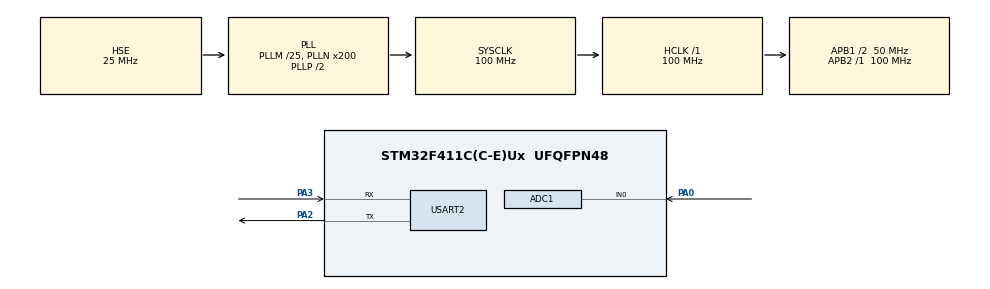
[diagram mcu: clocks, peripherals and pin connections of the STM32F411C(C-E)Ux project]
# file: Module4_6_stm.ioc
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ADC1.Channel-0\#ChannelRegularConversion=ADC_CHANNEL_0
ADC1.ContinuousConvMode=ENABLE
ADC1.DMAContinuousRequests=ENABLE
ADC1.NbrOfConversionFlag=1
ADC1.Rank-0\#ChannelRegularConversion=1
ADC1.SamplingTime-0\#ChannelRegularConversion=ADC_SAMPLETIME_84CYCLES
ADC1.master=1
Dma.ADC1.0.Direction=DMA_PERIPH_TO_MEMORY
Dma.ADC1.0.FIFOMode=DMA_FIFOMODE_DISABLE
Dma.ADC1.0.Instance=DMA2_Stream0
Dma.ADC1.0.MemDataAlignment=DMA_MDATAALIGN_HALFWORD
Dma.ADC1.0.MemInc=DMA_MINC_ENABLE
Dma.ADC1.0.Mode=DMA_CIRCULAR
Dma.ADC1.0.PeriphDataAlignment=DMA_PDATAALIGN_HALFWORD
Dma.ADC1.0.PeriphInc=DMA_PINC_DISABLE
Dma.ADC1.0.Priority=DMA_PRIORITY_LOW
Dma.Request0=ADC1
Dma.Request1=USART2_TX
Dma.USART2_TX.1.Direction=DMA_MEMORY_TO_PERIPH
Dma.USART2_TX.1.FIFOMode=DMA_FIFOMODE_DISABLE
Dma.USART2_TX.1.Instance=DMA1_Stream6
Dma.USART2_TX.1.MemDataAlignment=DMA_MDATAALIGN_BYTE
Dma.USART2_TX.1.MemInc=DMA_MINC_ENABLE
Dma.USART2_TX.1.Mode=DMA_NORMAL
Dma.USART2_TX.1.PeriphDataAlignment=DMA_PDATAALIGN_BYTE
Dma.USART2_TX.1.PeriphInc=DMA_PINC_DISABLE
Dma.USART2_TX.1.Priority=DMA_PRIORITY_LOW
Mcu.Family=STM32F4
Mcu.Name=STM32F411C(C-E)Ux
Mcu.Package=UFQFPN48
NVIC.DMA1_Stream6_IRQn=true\:0\:0\:false\:false\:true\:false\:true\:true
NVIC.DMA2_Stream0_IRQn=true\:0\:0\:false\:false\:true\:false\:true\:true
NVIC.PriorityGroup=NVIC_PRIORITYGROUP_4
NVIC.USART2_IRQn=true\:0\:0\:false\:false\:true\:false\:true\:true
PA0-WKUP.Signal=ADCx_IN0
PA13.Mode=Serial_Wire
PA13.Signal=SYS_JTMS-SWDIO
PA14.Mode=Serial_Wire
PA14.Signal=SYS_JTCK-SWCLK
PA2.Mode=Asynchronous
PA2.Signal=USART2_TX
PA3.Mode=Asynchronous
PA3.Signal=USART2_RX
PH0\ -\ OSC_IN.Mode=HSE-External-Oscillator
PH0\ -\ OSC_IN.Signal=RCC_OSC_IN
PH1\ -\ OSC_OUT.Mode=HSE-External-Oscillator
PH1\ -\ OSC_OUT.Signal=RCC_OSC_OUT
ProjectManager.HeapSize=0x200
ProjectManager.StackSize=0x400
ProjectManager.TargetToolchain=STM32CubeIDE
RCC.48MHZClocksFreq_Value=50000000
RCC.AHBFreq_Value=100000000
RCC.APB1CLKDivider=RCC_HCLK_DIV2
RCC.APB1Freq_Value=50000000
RCC.APB1TimFreq_Value=100000000
RCC.APB2Freq_Value=100000000
RCC.APB2TimFreq_Value=100000000
RCC.CortexFreq_Value=100000000
RCC.HCLKFreq_Value=100000000
RCC.HSE_VALUE=25000000
RCC.HSI_VALUE=16000000
RCC.LSE_VALUE=32768
RCC.PLLM=25
RCC.PLLN=200
RCC.PLLSourceVirtual=RCC_PLLSOURCE_HSE
RCC.SYSCLKFreq_VALUE=100000000
RCC.SYSCLKSource=RCC_SYSCLKSOURCE_PLLCLK
RCC.VCOOutputFreq_Value=200000000
SH.ADCx_IN0.0=ADC1_IN0,IN0
USART2.VirtualMode=VM_ASYNC
board=custom

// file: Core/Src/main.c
/* USER CODE BEGIN Header */
/**
  ******************************************************************************
  * @file           : main.c
  * @brief          : Main program body
  ******************************************************************************
  * @attention
  *
  * Copyright (c) 2026 STMicroelectronics.
  * All rights reserved.
  *
  * This software is licensed under terms that can be found in the LICENSE file
  * in the root directory of this software component.
  * If no LICENSE file comes with this software, it is provided AS-IS.
  *
  ******************************************************************************
  */
/* USER CODE END Header */
#include "main.h"

/* USER CODE BEGIN Includes */
#include <stdio.h>
#include <string.h>

/* USER CODE END Includes */

/* USER CODE BEGIN PD */
#define ADC_BUF_LEN   16      // кількість вибірок у кільцевому буфері
#define TX_BUF_LEN   64
#define VREF_MV       3300U
#define ADC_MAX       4095U
#define PRINT_PERIOD  200     // мс
/* USER CODE END PD */

ADC_HandleTypeDef hadc1;
DMA_HandleTypeDef hdma_adc1;

UART_HandleTypeDef huart2;
DMA_HandleTypeDef hdma_usart2_tx;

/* USER CODE BEGIN PV */
static uint16_t adc_buf[ADC_BUF_LEN];          // сюди пише DMA (ADC)
static char     tx_buf[TX_BUF_LEN];                    // звідси читає DMA (UART)
static volatile uint8_t uart_busy = 0;
/* USER CODE END PV */

void SystemClock_Config(void);
static void MX_GPIO_Init(void);
static void MX_DMA_Init(void);
static void MX_ADC1_Init(void);
static void MX_USART2_UART_Init(void);

/* USER CODE BEGIN 0 */
/* Викликається, коли DMA завершив передачу по UART */
void HAL_UART_TxCpltCallback(UART_HandleTypeDef *huart)
{
    if (huart->Instance == USART2) {
        uart_busy = 0;
    }
}

static uint16_t adc_average(void)
{
    uint32_t sum = 0;
    for (uint8_t i = 0; i < ADC_BUF_LEN; i++) {
        sum += adc_buf[i];
    }
    return (uint16_t)(sum / ADC_BUF_LEN);
}
/* USER CODE END 0 */

int main(void)
{

  /* MCU Configuration--------------------------------------------------------*/

  /* Reset of all peripherals, Initializes the Flash interface and the Systick. */
  HAL_Init();

  /* Configure the system clock */
  SystemClock_Config();

  /* Initialize all configured peripherals */
  MX_GPIO_Init();
  MX_DMA_Init();
  MX_ADC1_Init();
  MX_USART2_UART_Init();
  /* USER CODE BEGIN 2 */
    HAL_ADC_Start_DMA(&hadc1, (uint32_t *)adc_buf, ADC_BUF_LEN);
    uint32_t last_tick = HAL_GetTick();
  /* USER CODE END 2 */

  /* Infinite loop */
  while (1)
  {

    /* USER CODE BEGIN 3 */
          if ((HAL_GetTick() - last_tick >= PRINT_PERIOD) && !uart_busy)
          {
              last_tick = HAL_GetTick();

              uint16_t raw = adc_average();
              uint32_t mv  = (uint32_t)raw * VREF_MV / ADC_MAX;

              int len = snprintf(tx_buf, sizeof(tx_buf),
                                 "ADC: %4u | %lu mV\r\n",
                                 raw, (unsigned long)mv);

              if (len > 0) {
                  uart_busy = 1;
                  if (HAL_UART_Transmit_DMA(&huart2, (uint8_t *)tx_buf, (uint16_t)len) != HAL_OK) {
                      uart_busy = 0;
                  }
              }
          }
  /* USER CODE END 3 */
}
}

void SystemClock_Config(void)
{
  RCC_OscInitTypeDef RCC_OscInitStruct = {0};
  RCC_ClkInitTypeDef RCC_ClkInitStruct = {0};

  /** Configure the main internal regulator output voltage
  */
  __HAL_RCC_PWR_CLK_ENABLE();
  __HAL_PWR_VOLTAGESCALING_CONFIG(PWR_REGULATOR_VOLTAGE_SCALE1);

  /** Initializes the RCC Oscillators according to the specified parameters
  * in the RCC_OscInitTypeDef structure.
  */
  RCC_OscInitStruct.OscillatorType = RCC_OSCILLATORTYPE_HSE;
  RCC_OscInitStruct.HSEState = RCC_HSE_ON;
  RCC_OscInitStruct.PLL.PLLState = RCC_PLL_ON;
  RCC_OscInitStruct.PLL.PLLSource = RCC_PLLSOURCE_HSE;
  RCC_OscInitStruct.PLL.PLLM = 25;
  RCC_OscInitStruct.PLL.PLLN = 200;
  RCC_OscInitStruct.PLL.PLLP = RCC_PLLP_DIV2;
  RCC_OscInitStruct.PLL.PLLQ = 4;
  if (HAL_RCC_OscConfig(&RCC_OscInitStruct) != HAL_OK)
  {
    Error_Handler();
  }

  /** Initializes the CPU, AHB and APB buses clocks
  */
  RCC_ClkInitStruct.ClockType = RCC_CLOCKTYPE_HCLK|RCC_CLOCKTYPE_SYSCLK
                              |RCC_CLOCKTYPE_PCLK1|RCC_CLOCKTYPE_PCLK2;
  RCC_ClkInitStruct.SYSCLKSource = RCC_SYSCLKSOURCE_PLLCLK;
  RCC_ClkInitStruct.AHBCLKDivider = RCC_SYSCLK_DIV1;
  RCC_ClkInitStruct.APB1CLKDivider = RCC_HCLK_DIV2;
  RCC_ClkInitStruct.APB2CLKDivider = RCC_HCLK_DIV1;

  if (HAL_RCC_ClockConfig(&RCC_ClkInitStruct, FLASH_LATENCY_3) != HAL_OK)
  {
    Error_Handler();
  }
}

static void MX_ADC1_Init(void)
{

  ADC_ChannelConfTypeDef sConfig = {0};

  /** Configure the global features of the ADC (Clock, Resolution, Data Alignment and number of conversion)
  */
  hadc1.Instance = ADC1;
  hadc1.Init.ClockPrescaler = ADC_CLOCK_SYNC_PCLK_DIV4;
  hadc1.Init.Resolution = ADC_RESOLUTION_12B;
  hadc1.Init.ScanConvMode = DISABLE;
  hadc1.Init.ContinuousConvMode = ENABLE;
  hadc1.Init.DiscontinuousConvMode = DISABLE;
  hadc1.Init.ExternalTrigConvEdge = ADC_EXTERNALTRIGCONVEDGE_NONE;
  hadc1.Init.ExternalTrigConv = ADC_SOFTWARE_START;
  hadc1.Init.DataAlign = ADC_DATAALIGN_RIGHT;
  hadc1.Init.NbrOfConversion = 1;
  hadc1.Init.DMAContinuousRequests = ENABLE;
  hadc1.Init.EOCSelection = ADC_EOC_SINGLE_CONV;
  if (HAL_ADC_Init(&hadc1) != HAL_OK)
  {
    Error_Handler();
  }

  /** Configure for the selected ADC regular channel its corresponding rank in the sequencer and its sample time.
  */
  sConfig.Channel = ADC_CHANNEL_0;
  sConfig.Rank = 1;
  sConfig.SamplingTime = ADC_SAMPLETIME_84CYCLES;
  if (HAL_ADC_ConfigChannel(&hadc1, &sConfig) != HAL_OK)
  {
    Error_Handler();
  }

}

static void MX_USART2_UART_Init(void)
{

  huart2.Instance = USART2;
  huart2.Init.BaudRate = 115200;
  huart2.Init.WordLength = UART_WORDLENGTH_8B;
  huart2.Init.StopBits = UART_STOPBITS_1;
  huart2.Init.Parity = UART_PARITY_NONE;
  huart2.Init.Mode = UART_MODE_TX_RX;
  huart2.Init.HwFlowCtl = UART_HWCONTROL_NONE;
  huart2.Init.OverSampling = UART_OVERSAMPLING_16;
  if (HAL_UART_Init(&huart2) != HAL_OK)
  {
    Error_Handler();
  }

}

static void MX_DMA_Init(void)
{

  /* DMA controller clock enable */
  __HAL_RCC_DMA2_CLK_ENABLE();
  __HAL_RCC_DMA1_CLK_ENABLE();

  /* DMA interrupt init */
  /* DMA1_Stream6_IRQn interrupt configuration */
  HAL_NVIC_SetPriority(DMA1_Stream6_IRQn, 0, 0);
  HAL_NVIC_EnableIRQ(DMA1_Stream6_IRQn);
  /* DMA2_Stream0_IRQn interrupt configuration */
  HAL_NVIC_SetPriority(DMA2_Stream0_IRQn, 0, 0);
  HAL_NVIC_EnableIRQ(DMA2_Stream0_IRQn);

}

static void MX_GPIO_Init(void)
{

  /* GPIO Ports Clock Enable */
  __HAL_RCC_GPIOH_CLK_ENABLE();
  __HAL_RCC_GPIOA_CLK_ENABLE();

}

void Error_Handler(void)
{
  __disable_irq();
  while (1)
  {
  }
}
